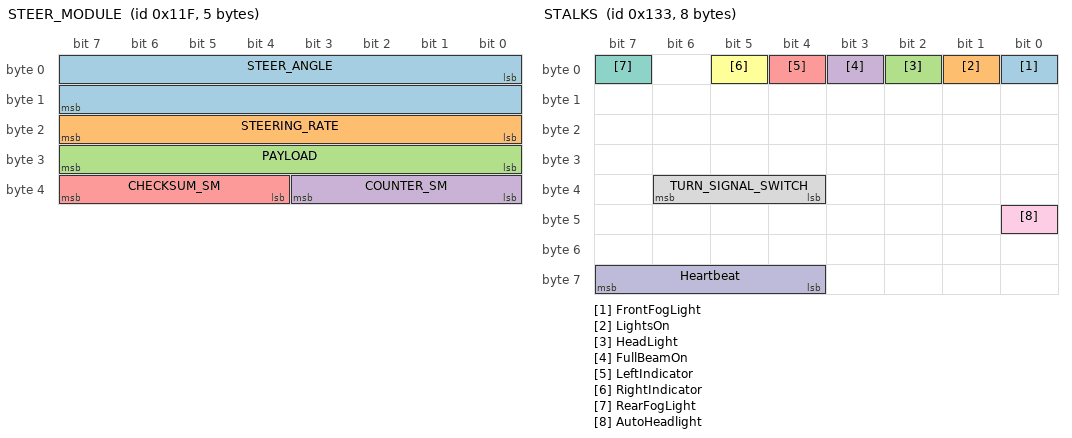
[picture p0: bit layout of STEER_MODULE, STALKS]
BO_ 287 STEER_MODULE: 5 XXX
 SG_ STEER_ANGLE : 0|16@1- (0.1,0) [-450|450] "" XXX
 SG_ STEERING_RATE : 16|8@1+ (4,0) [0|1020] "" XXX
 SG_ PAYLOAD : 24|8@1+ (1,0) [0|255] "" XXX
 SG_ COUNTER_SM : 32|4@1+ (1,0) [0|255] "" XXX
 SG_ CHECKSUM_SM : 36|4@1+ (1,0) [0|15] "" XXX

BO_ 307 STALKS: 8 XXX
 SG_ FrontFogLight : 0|1@0+ (1,0) [0|1] "" XXX
 SG_ LightsOn : 1|1@1+ (1,0) [0|1] "" XXX
 SG_ HeadLight : 2|1@1+ (1,0) [0|1] "" XXX
 SG_ FullBeamOn : 3|1@1+ (1,0) [0|1] "" XXX
 SG_ LeftIndicator : 4|1@0+ (1,0) [0|1] "" XXX
 SG_ RightIndicator : 5|1@0+ (1,0) [0|1] "" XXX
 SG_ RearFogLight : 7|1@0+ (1,0) [0|1] "" XXX
 SG_ TURN_SIGNAL_SWITCH : 36|3@1+ (1,0) [0|7] "" XXX
 SG_ AutoHeadlight : 40|1@0+ (1,0) [0|1] "" XXX
 SG_ Heartbeat : 63|4@0+ (1,0) [0|15] "" XXX

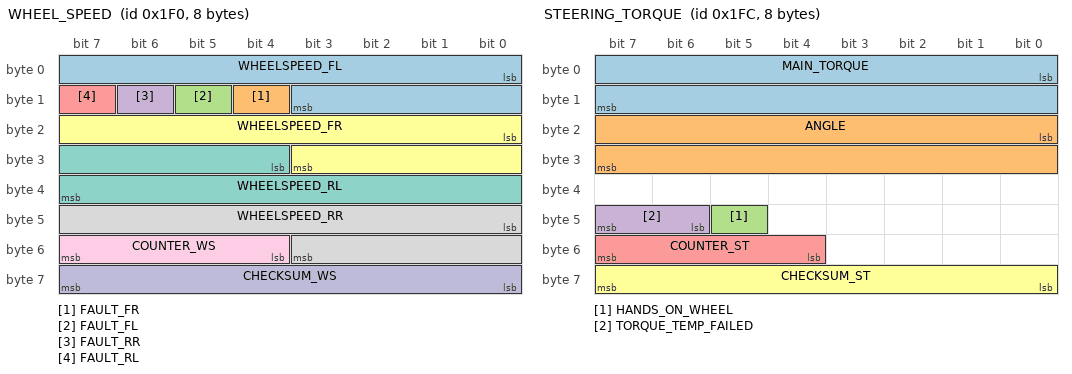
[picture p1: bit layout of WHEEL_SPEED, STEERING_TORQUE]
BO_ 496 WHEEL_SPEED: 8 XXX
 SG_ WHEELSPEED_FL : 0|12@1+ (0.1,0) [0|281.4625] "km/h" XXX
 SG_ FAULT_FR : 12|1@1+ (1,0) [0|1] "" XXX
 SG_ FAULT_FL : 13|1@1+ (1,0) [0|1] "" XXX
 SG_ FAULT_RR : 14|1@1+ (1,0) [0|1] "" XXX
 SG_ FAULT_RL : 15|1@1+ (1,0) [0|1] "" XXX
 SG_ WHEELSPEED_FR : 16|12@1+ (0.1,0) [0|281.4625] "km/h" XXX
 SG_ WHEELSPEED_RL : 28|12@1+ (0.1,0) [0|281.4625] "km/h" XXX
 SG_ WHEELSPEED_RR : 40|12@1+ (0.1,0) [0|281.4625] "km/h" XXX
 SG_ COUNTER_WS : 55|4@0+ (1,0) [0|15] "" XXX
 SG_ CHECKSUM_WS : 63|8@0+ (1,0) [0|255] "" XXX

BO_ 508 STEERING_TORQUE: 8 XXX
 SG_ MAIN_TORQUE : 0|16@1- (0.1,0) [0|65535] "" XXX
 SG_ ANGLE : 16|16@1- (0.1,0) [0|255] "" XXX
 SG_ HANDS_ON_WHEEL : 45|1@1+ (1,0) [0|255] "" XXX
 SG_ TORQUE_TEMP_FAILED : 46|2@1+ (1,0) [0|3] "" XXX
 SG_ COUNTER_ST : 55|4@0+ (1,0) [0|15] "" XXX
 SG_ CHECKSUM_ST : 63|8@0+ (1,0) [0|255] "" XXX

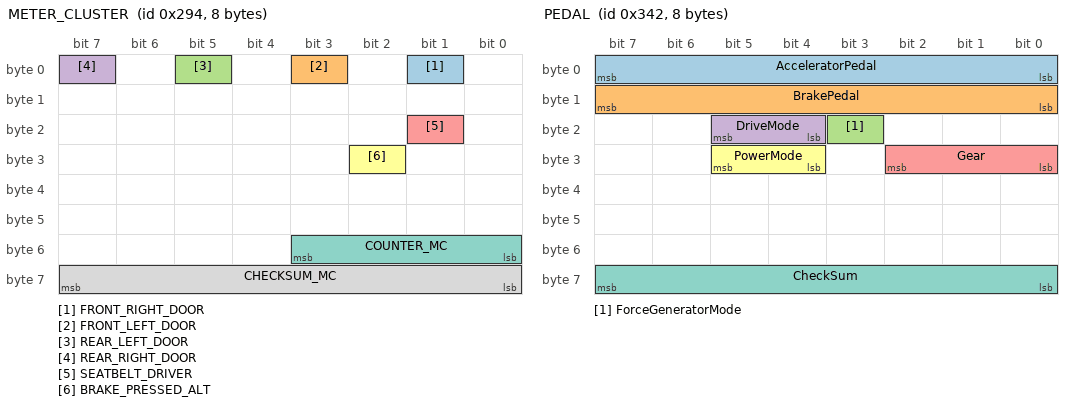
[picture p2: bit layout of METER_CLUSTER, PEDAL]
BO_ 660 METER_CLUSTER: 8 XXX
 SG_ FRONT_RIGHT_DOOR : 1|1@1+ (1,0) [0|511] "" XXX
 SG_ FRONT_LEFT_DOOR : 3|1@0+ (1,0) [0|1] "" XXX
 SG_ REAR_LEFT_DOOR : 5|1@1+ (1,0) [0|511] "" XXX
 SG_ REAR_RIGHT_DOOR : 7|1@0+ (1,0) [0|1] "" XXX
 SG_ SEATBELT_DRIVER : 17|1@0+ (1,0) [0|1] "" XXX
 SG_ BRAKE_PRESSED_ALT : 26|1@1+ (1,0) [0|1] "" XXX
 SG_ COUNTER_MC : 48|4@1+ (1,0) [0|255] "" XXX
 SG_ CHECKSUM_MC : 56|8@1+ (1,0) [0|255] "" XXX

BO_ 834 PEDAL: 8 XXX
 SG_ AcceleratorPedal : 0|8@1+ (0.01,0) [0|2.55] "" XXX
 SG_ BrakePedal : 8|8@1+ (0.01,0) [0|2.55] "" XXX
 SG_ ForceGeneratorMode : 19|1@1+ (1,0) [0|1] "" XXX
 SG_ DriveMode : 20|2@1+ (1,0) [0|255] "" XXX
 SG_ Gear : 26|3@0+ (1,0) [0|7] "" XXX
 SG_ PowerMode : 28|2@1+ (1,0) [0|1] "" XXX
 SG_ CheckSum : 56|8@1+ (1,0) [0|255] "" XXX

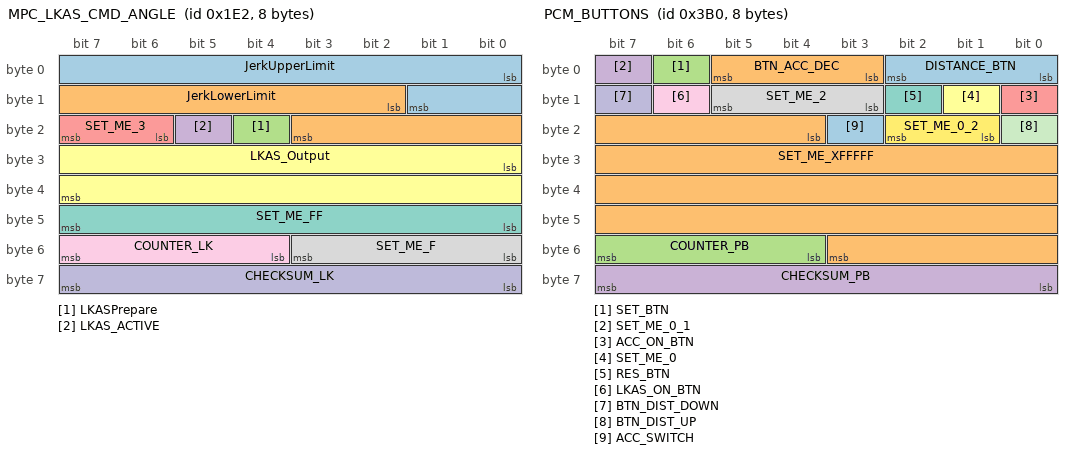
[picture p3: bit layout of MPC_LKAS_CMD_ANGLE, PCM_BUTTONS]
BO_ 482 MPC_LKAS_CMD_ANGLE: 8 XXX
 SG_ JerkUpperLimit : 0|10@1- (1,0) [0|65535] "" XXX
 SG_ JerkLowerLimit : 10|10@1- (1,0) [0|15] "" XXX
 SG_ LKASPrepare : 20|1@0+ (1,0) [0|1] "" XXX
 SG_ LKAS_ACTIVE : 21|1@0+ (1,0) [0|1] "" XXX
 SG_ SET_ME_3 : 22|2@1+ (1,0) [0|1] "" XXX
 SG_ LKAS_Output : 24|16@1- (0.1,0) [0|255] "" XXX
 SG_ SET_ME_FF : 47|8@0+ (1,0) [0|255] "" XXX
 SG_ SET_ME_F : 48|4@1+ (1,0) [0|15] "" XXX
 SG_ COUNTER_LK : 52|4@1+ (1,0) [0|15] "" XXX
 SG_ CHECKSUM_LK : 56|8@1+ (1,0) [0|255] "" XXX

BO_ 813 ACC_HUD_ADAS: 8 XXX
 SG_ SET_SPEED : 0|9@1+ (0.5,0) [0|255.5] "" XXX
 SG_ HAS_LEAD : 9|1@1+ (1,0) [0|1] "" XXX
 SG_ SET_DISTANCE : 10|3@1+ (1,0) [0|7] "" XXX
 SG_ LEAD_DISTANCE : 13|3@1+ (1,0) [0|7] "" XXX
 SG_ AEB : 16|1@1+ (1,0) [0|1] "" XXX
 SG_ FCW : 17|1@1+ (1,0) [0|1] "" XXX
 SG_ SET_ME_1 : 18|1@1+ (1,0) [0|1] "" XXX
 SG_ ACC_ON2 : 19|1@0+ (1,0) [0|1] "" XXX
 SG_ ACC_CONTROLLABLE_AND_ON : 20|1@1+ (1,0) [0|1] "" XXX
 SG_ OVERRIDE : 21|1@1+ (1,0) [0|1] "" XXX
 SG_ ACC_ON1 : 22|1@0+ (1,0) [0|1] "" XXX
 SG_ TOO_CLOSE : 23|1@0+ (1,0) [0|1] "" XXX
 SG_ SET_ME_1_1 : 24|3@1+ (1,0) [0|1] "" XXX
 SG_ NOTIFY : 27|5@1+ (1,0) [0|127] "" XXX
 SG_ ERROR : 32|4@1+ (1,0) [0|15] "" XXX
 SG_ SET_ME_XFF : 36|8@1+ (1,0) [0|4095] "" XXX
 SG_ CRUISE_STATE : 44|4@1+ (1,0) [0|15] "" XXX
 SG_ COUNTER_CAM : 48|4@1+ (1,0) [0|15] "" XXX
 SG_ SET_ME_XF : 55|4@0+ (1,0) [0|15] "" XXX
 SG_ CHECKSUM_CAM : 56|8@1+ (1,0) [0|255] "" XXX

BO_ 944 PCM_BUTTONS: 8 XXX
 SG_ DISTANCE_BTN : 0|3@1+ (1,0) [0|7] "" XXX
 SG_ BTN_ACC_DEC : 3|3@1+ (1,0) [0|7] "" XXX
 SG_ SET_BTN : 6|1@0+ (1,0) [0|1] "" XXX
 SG_ SET_ME_0_1 : 7|1@1+ (1,0) [0|1] "" XXX
 SG_ ACC_ON_BTN : 8|1@0+ (1,0) [0|1] "" XXX
 SG_ SET_ME_0 : 9|1@1+ (1,0) [0|1] "" XXX
 SG_ RES_BTN : 10|1@0+ (1,0) [0|1] "" XXX
 SG_ SET_ME_2 : 11|3@1+ (1,0) [0|7] "" XXX
 SG_ LKAS_ON_BTN : 14|1@0+ (1,0) [0|1] "" XXX
 SG_ BTN_DIST_DOWN : 15|1@1+ (1,0) [0|1] "" XXX
 SG_ BTN_DIST_UP : 16|1@1+ (1,0) [0|1] "" XXX
 SG_ SET_ME_0_2 : 17|2@1+ (1,0) [0|1] "" XXX
 SG_ ACC_SWITCH : 19|1@1+ (1,0) [0|1] "" XXX
 SG_ SET_ME_XFFFFF : 20|32@1+ (1,0) [0|68719476735] "" XXX
 SG_ COUNTER_PB : 52|4@1+ (1,0) [0|15] "" XXX
 SG_ CHECKSUM_PB : 56|8@1+ (1,0) [0|255] "" XXX

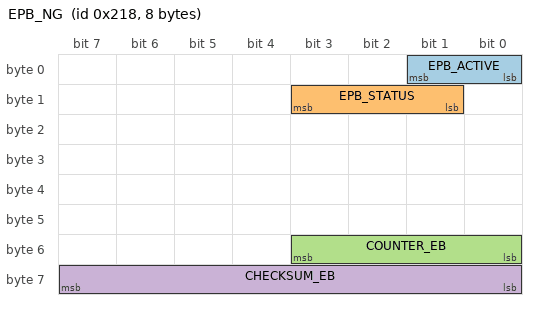
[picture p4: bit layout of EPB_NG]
BO_ 536 EPB_NG: 8 XXX
 SG_ EPB_ACTIVE : 0|2@1+ (1,0) [0|3] "" XXX
 SG_ EPB_STATUS : 9|3@1+ (1,0) [0|7] "" XXX
 SG_ COUNTER_EB : 48|4@1+ (1,0) [0|15] "" XXX
 SG_ CHECKSUM_EB : 56|8@1+ (1,0) [0|255] "" XXX

VAL_ 307 TURN_SIGNAL_SWITCH 0 "Invalid" 1 "OFFGear" 2 "LeftSteeringShortLift" 3 "LeftSteeringLongLift" 4 "RightSteeringShortLift" 5 "RightSteeringLongLift" 7 "Unavaliable";
VAL_ 536 EPB_ACTIVE 0 "NotActive" 1 "Release" 2 "Apply" 3 "Reserved";
VAL_ 536 EPB_STATUS 0 "Releasing" 1 "Released" 2 "Applying" 3 "Applied" 4 "FaultProhibitionOfRemoteDriving";
VAL_ 834 Gear 4 "D" 2 "R" 1 "P";
VAL_ 834 DriveMode 2 "SPORT" 1 "ECO" 0 "SNOW" ;
VAL_ 834 PowerMode 3 "HEV" 2 "FORCE_EV" 1 "EV" ;
